# LPC176x5x register map
File version: 0.2
LPC176x/LPC175x M3
CPU: CM3 r0p0, little endian, MPU, no FPU, 5 interrupt priority bits
Registers are 32-bit, read-write, reset 0x0 unless marked. A register's access mark holds for its fields unless they carry their own. Offsets are from the block's base; lines under a group give offsets from that group; [hi:lo] are bit positions; {n}, {i} and the like mark numbered series; 'fields as' and 'values as' point back to an identical list; <NAME> marks a mode.

## Memory map
0x40000000 WDT size 0xFFF — Watchdog Timer (WDT)

## Interrupts
0 WDT

## WDT — Watchdog Timer (WDT)
Base 0x40000000
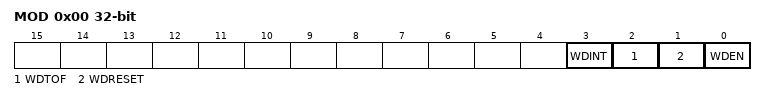
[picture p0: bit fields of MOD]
0x00 MOD — Watchdog mode register. This register determines the basic mode and status of the Watchdog Timer.
  [3] WDINT — Watchdog interrupt flag. Cleared by software.
  [2] WDTOF — Watchdog time-out flag. Set when the watchdog timer times out, cleared by software.
  [1] WDRESET — Watchdog reset enable bit. This bit is Set Only. See Table 652.
    0=NORESET (A watchdog timeout will not cause a chip reset.); 1=RESET (A watchdog timeout will cause a chip reset.)
  [0] WDEN — Watchdog enable bit. This bit is Set Only.
    0=STOP (The watchdog timer is stopped.); 1=RUN (The watchdog timer is running.)
0x04 TC reset 0xFF — Watchdog timer constant register. The value in this register determines the time-out value.
  [31:0] Count — Watchdog time-out interval.
0x08 FEED wo reset not defined — Watchdog feed sequence register. Writing 0xAA followed by 0x55 to this register reloads the Watchdog timer with the value contained in WDTC.
  [7:0] Feed — Feed value should be 0xAA followed by 0x55.
0x0C TV ro reset 0xFF — Watchdog timer value register. This register reads out the current value of the Watchdog timer.
  [31:0] Count — Counter timer value.
0x10 CLKSEL — Watchdog clock select register.
  [31] LOCK — If this bit is set to one writing to this register does not affect bit 0. The clock source can only be changed by first clearing this bit, then writing the new value of bit 0.
    0=UNLOCKED (This bit is set to 0 on any reset. It cannot be cleared by software.); 1=LOCKED (Software can set this bit to 1 at any time. Once WDLOCK is set, the bits of this register cannot be modified.)
  [30:1] RESERVED — Reserved, user software should not write ones to reserved bits. The value read from a reserved bit is not defined.
  [1:0] CLKSEL — Selects source of WDT clock
    0=IRC; 1=PCLK (Peripheral clock); 2=RTCOSC (RTC oscillator)
